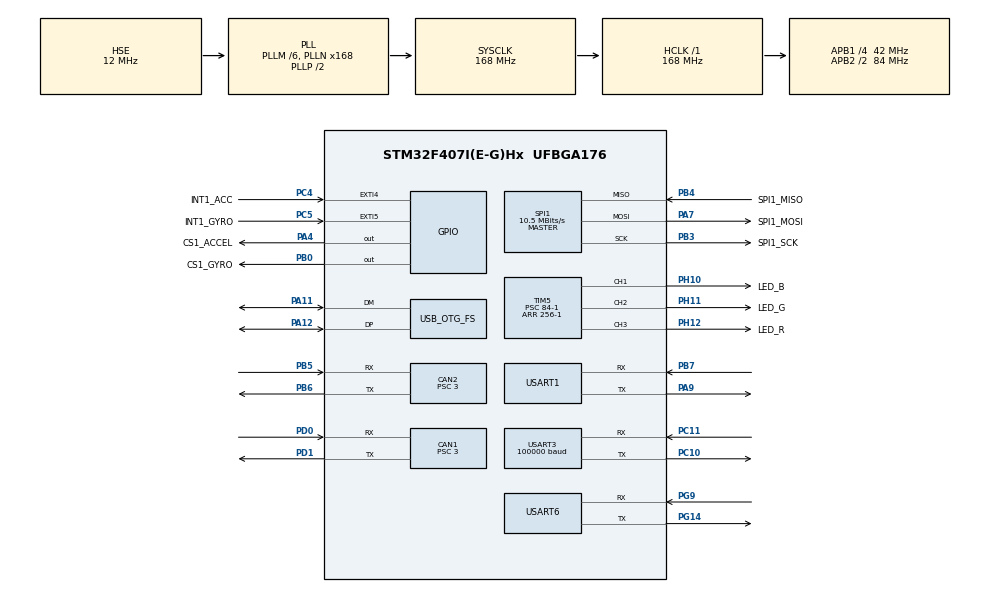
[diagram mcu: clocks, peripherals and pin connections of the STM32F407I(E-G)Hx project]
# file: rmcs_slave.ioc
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CAN1.BS1=CAN_BS1_9TQ
CAN1.BS2=CAN_BS2_4TQ
CAN1.CalculateBaudRate=1000000
CAN1.CalculateTimeBit=1000
CAN1.CalculateTimeQuantum=71.42857142857143
CAN1.NART=DISABLE
CAN1.Prescaler=3
CAN2.BS1=CAN_BS1_9TQ
CAN2.BS2=CAN_BS2_4TQ
CAN2.CalculateBaudRate=1000000
CAN2.CalculateTimeBit=1000
CAN2.CalculateTimeQuantum=71.42857142857143
CAN2.NART=DISABLE
CAN2.Prescaler=3
Mcu.Family=STM32F4
Mcu.Name=STM32F407I(E-G)Hx
Mcu.Package=UFBGA176
NVIC.CAN1_RX0_IRQn=true\:2\:0\:true\:false\:true\:true\:true\:true
NVIC.CAN2_RX0_IRQn=true\:2\:0\:true\:false\:true\:true\:true\:true
NVIC.EXTI4_IRQn=true\:4\:0\:true\:false\:true\:true\:true\:true
NVIC.EXTI9_5_IRQn=true\:4\:0\:true\:false\:true\:true\:true\:true
NVIC.PriorityGroup=NVIC_PRIORITYGROUP_4
NVIC.SPI1_IRQn=true\:4\:0\:true\:false\:true\:true\:true\:true
NVIC.USART1_IRQn=true\:6\:0\:true\:false\:true\:true\:true\:true
NVIC.USART3_IRQn=true\:6\:0\:true\:false\:true\:true\:true\:true
NVIC.USART6_IRQn=true\:6\:0\:true\:false\:true\:true\:true\:true
PA11.Mode=Device_Only
PA11.Signal=USB_OTG_FS_DM
PA12.Mode=Device_Only
PA12.Signal=USB_OTG_FS_DP
PA13.Mode=Serial_Wire
PA13.Signal=SYS_JTMS-SWDIO
PA14.Mode=Serial_Wire
PA14.Signal=SYS_JTCK-SWCLK
PA4.GPIO_Label=CS1_ACCEL
PA4.GPIO_PuPd=GPIO_PULLUP
PA4.GPIO_Speed=GPIO_SPEED_FREQ_VERY_HIGH
PA4.PinState=GPIO_PIN_SET
PA4.Signal=GPIO_Output
PA7.GPIO_Label=SPI1_MOSI
PA7.Mode=Full_Duplex_Master
PA7.Signal=SPI1_MOSI
PA9.Mode=Asynchronous
PA9.Signal=USART1_TX
PB0.GPIO_Label=CS1_GYRO
PB0.GPIO_PuPd=GPIO_PULLUP
PB0.GPIO_Speed=GPIO_SPEED_FREQ_VERY_HIGH
PB0.PinState=GPIO_PIN_SET
PB0.Signal=GPIO_Output
PB3.GPIO_Label=SPI1_SCK
PB3.Mode=Full_Duplex_Master
PB3.Signal=SPI1_SCK
PB4.GPIO_Label=SPI1_MISO
PB4.Mode=Full_Duplex_Master
PB4.Signal=SPI1_MISO
PB5.Mode=CAN_Activate
PB5.Signal=CAN2_RX
PB6.Mode=CAN_Activate
PB6.Signal=CAN2_TX
PB7.Mode=Asynchronous
PB7.Signal=USART1_RX
PC10.Mode=Asynchronous
PC10.Signal=USART3_TX
PC11.Mode=Asynchronous
PC11.Signal=USART3_RX
PC4.GPIO_Label=INT1_ACC
PC4.Signal=GPXTI4
PC5.GPIO_Label=INT1_GYRO
PC5.Signal=GPXTI5
PD0.Mode=CAN_Activate
PD0.Signal=CAN1_RX
PD1.Mode=CAN_Activate
PD1.Signal=CAN1_TX
PG14.Mode=Asynchronous
PG14.Signal=USART6_TX
PG9.Mode=Asynchronous
PG9.Signal=USART6_RX
PH0-OSC_IN.Mode=HSE-External-Oscillator
PH0-OSC_IN.Signal=RCC_OSC_IN
PH1-OSC_OUT.Mode=HSE-External-Oscillator
PH1-OSC_OUT.Signal=RCC_OSC_OUT
PH10.GPIO_Label=LED_B
PH10.Signal=S_TIM5_CH1
PH11.GPIO_Label=LED_G
PH11.Signal=S_TIM5_CH2
PH12.GPIO_Label=LED_R
PH12.Signal=S_TIM5_CH3
ProjectManager.HeapSize=0x200
ProjectManager.StackSize=0x400
ProjectManager.TargetToolchain=Makefile
RCC.48MHZClocksFreq_Value=48000000
RCC.AHBFreq_Value=168000000
RCC.APB1CLKDivider=RCC_HCLK_DIV4
RCC.APB1Freq_Value=42000000
RCC.APB1TimFreq_Value=84000000
RCC.APB2CLKDivider=RCC_HCLK_DIV2
RCC.APB2Freq_Value=84000000
RCC.APB2TimFreq_Value=168000000
RCC.CortexFreq_Value=168000000
RCC.HCLKFreq_Value=168000000
RCC.HSE_VALUE=12000000
RCC.HSI_VALUE=16000000
RCC.LSE_VALUE=32768
RCC.PLLM=6
RCC.PLLN=168
RCC.PLLQ=7
RCC.SYSCLKFreq_VALUE=168000000
RCC.SYSCLKSource=RCC_SYSCLKSOURCE_PLLCLK
RCC.VCOOutputFreq_Value=336000000
SH.S_TIM5_CH1.0=TIM5_CH1,PWM Generation1 CH1
SH.S_TIM5_CH2.0=TIM5_CH2,PWM Generation2 CH2
SH.S_TIM5_CH3.0=TIM5_CH3,PWM Generation3 CH3
SPI1.BaudRatePrescaler=SPI_BAUDRATEPRESCALER_8
SPI1.CLKPhase=SPI_PHASE_2EDGE
SPI1.CLKPolarity=SPI_POLARITY_HIGH
SPI1.CalculateBaudRate=10.5 MBits/s
SPI1.Direction=SPI_DIRECTION_2LINES
SPI1.Mode=SPI_MODE_MASTER
SPI1.VirtualType=VM_MASTER
TIM5.Channel-PWM\ Generation1\ CH1=TIM_CHANNEL_1
TIM5.Channel-PWM\ Generation2\ CH2=TIM_CHANNEL_2
TIM5.Channel-PWM\ Generation3\ CH3=TIM_CHANNEL_3
TIM5.Period=256-1
TIM5.Prescaler=84-1
USART1.VirtualMode=VM_ASYNC
USART3.BaudRate=100000
USART3.Parity=PARITY_EVEN
USART3.StopBits=STOPBITS_1
USART3.VirtualMode=VM_ASYNC
USART3.WordLength=WORDLENGTH_9B
USART6.VirtualMode=VM_ASYNC
USB_OTG_FS.VirtualMode=Device_Only
VP_TIM5_VS_ClockSourceINT.Mode=Internal
board=custom

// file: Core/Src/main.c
/* USER CODE BEGIN Header */
/**
  ******************************************************************************
  * @file           : main.c
  * @brief          : Main program body
  ******************************************************************************
  * @attention
  *
  * Copyright (c) 2023 STMicroelectronics.
  * All rights reserved.
  *
  * This software is licensed under terms that can be found in the LICENSE file
  * in the root directory of this software component.
  * If no LICENSE file comes with this software, it is provided AS-IS.
  *
  ******************************************************************************
  */
/* USER CODE END Header */
#include "main.h"
#include "can.h"
#include "spi.h"
#include "tim.h"
#include "usart.h"
#include "usb_otg.h"
#include "gpio.h"

/* USER CODE BEGIN Includes */
#include <assert.h>
/* USER CODE END Includes */

void SystemClock_Config(void);

int main(void)
{

  /* USER CODE BEGIN 1 */
  SCB->VTOR = 0x08010000U;

  /* USER CODE END 1 */

  /* MCU Configuration--------------------------------------------------------*/

  /* Reset of all peripherals, Initializes the Flash interface and the Systick. */
  HAL_Init();

  /* Configure the system clock */
  SystemClock_Config();

  /* USER CODE BEGIN SysInit */
  // Enable DWT (Data Watchpoint and Trace) for delay
  CoreDebug->DEMCR |= CoreDebug_DEMCR_TRCENA_Msk;
  DWT->CYCCNT = 0;
  DWT->CTRL |= DWT_CTRL_CYCCNTENA_Msk;

  /* USER CODE END SysInit */

  /* Initialize all configured peripherals */
  MX_GPIO_Init();
  MX_SPI1_Init();
  MX_CAN1_Init();
  MX_CAN2_Init();
  MX_USART1_UART_Init();
  MX_USART3_UART_Init();
  MX_USART6_UART_Init();
  MX_TIM5_Init();
  MX_USB_OTG_FS_PCD_Init();
  /* USER CODE BEGIN 2 */

  AppEntry();
  assert(0);

  /* USER CODE END 2 */

  /* Infinite loop */
  while (1)
  {

  }
}

void SystemClock_Config(void)
{
  RCC_OscInitTypeDef RCC_OscInitStruct = {0};
  RCC_ClkInitTypeDef RCC_ClkInitStruct = {0};

  /** Configure the main internal regulator output voltage
  */
  __HAL_RCC_PWR_CLK_ENABLE();
  __HAL_PWR_VOLTAGESCALING_CONFIG(PWR_REGULATOR_VOLTAGE_SCALE1);

  /** Initializes the RCC Oscillators according to the specified parameters
  * in the RCC_OscInitTypeDef structure.
  */
  RCC_OscInitStruct.OscillatorType = RCC_OSCILLATORTYPE_HSE;
  RCC_OscInitStruct.HSEState = RCC_HSE_ON;
  RCC_OscInitStruct.PLL.PLLState = RCC_PLL_ON;
  RCC_OscInitStruct.PLL.PLLSource = RCC_PLLSOURCE_HSE;
  RCC_OscInitStruct.PLL.PLLM = 6;
  RCC_OscInitStruct.PLL.PLLN = 168;
  RCC_OscInitStruct.PLL.PLLP = RCC_PLLP_DIV2;
  RCC_OscInitStruct.PLL.PLLQ = 7;
  if (HAL_RCC_OscConfig(&RCC_OscInitStruct) != HAL_OK)
  {
    Error_Handler();
  }

  /** Initializes the CPU, AHB and APB buses clocks
  */
  RCC_ClkInitStruct.ClockType = RCC_CLOCKTYPE_HCLK|RCC_CLOCKTYPE_SYSCLK
                              |RCC_CLOCKTYPE_PCLK1|RCC_CLOCKTYPE_PCLK2;
  RCC_ClkInitStruct.SYSCLKSource = RCC_SYSCLKSOURCE_PLLCLK;
  RCC_ClkInitStruct.AHBCLKDivider = RCC_SYSCLK_DIV1;
  RCC_ClkInitStruct.APB1CLKDivider = RCC_HCLK_DIV4;
  RCC_ClkInitStruct.APB2CLKDivider = RCC_HCLK_DIV2;

  if (HAL_RCC_ClockConfig(&RCC_ClkInitStruct, FLASH_LATENCY_5) != HAL_OK)
  {
    Error_Handler();
  }
}

void Error_Handler(void)
{
  __disable_irq();
  while (1)
  {
  }
}
